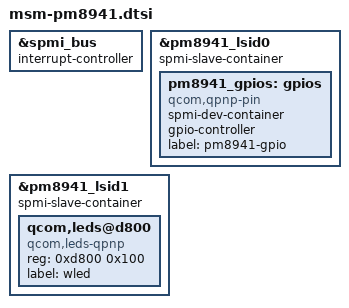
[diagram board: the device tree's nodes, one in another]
/* Copyright (c) 2012-2015, The Linux Foundation. All rights reserved.
 *
 * This program is free software; you can redistribute it and/or modify
 * it under the terms of the GNU General Public License version 2 and
 * only version 2 as published by the Free Software Foundation.
 *
 * This program is distributed in the hope that it will be useful,
 * but WITHOUT ANY WARRANTY; without even the implied warranty of
 * MERCHANTABILITY or FITNESS FOR A PARTICULAR PURPOSE.  See the
 * GNU General Public License for more details.
 */

&spmi_bus {
	#address-cells = <1>;
	#size-cells = <0>;
	interrupt-controller;
	#interrupt-cells = <3>;
};

&pm8941_lsid0 {
	spmi-slave-container;
	#address-cells = <1>;
	#size-cells = <1>;

	pm8941_gpios: gpios {
		spmi-dev-container;
		compatible = "qcom,qpnp-pin";
		gpio-controller;
		#gpio-cells = <2>;
		#address-cells = <1>;
		#size-cells = <1>;
		label = "pm8941-gpio";
	};
};

&pm8941_lsid1 {
	spmi-slave-container;
	#address-cells = <1>;
	#size-cells = <1>;

	qcom,leds@d800 {
		compatible = "qcom,leds-qpnp";
		reg = <0xd800 0x100>;
		label = "wled";
	};
};
